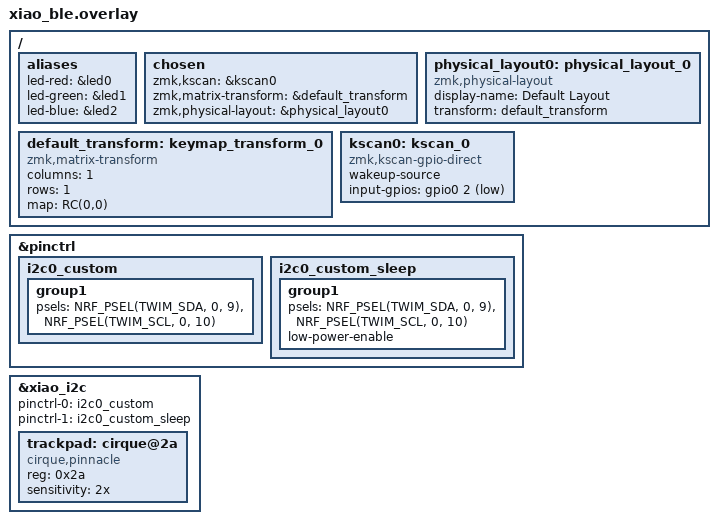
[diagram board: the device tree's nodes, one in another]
#include <dt-bindings/pinctrl/nrf-pinctrl.h>
#include <dt-bindings/zmk/matrix_transform.h>

/ {
    /* RGBLED Widget用のエイリアス設定（ハイフンを使用） */
    aliases {
        led-red = &led0;
        led-green = &led1;
        led-blue = &led2;
    };

    chosen {
        zmk,kscan = &kscan0;
        zmk,matrix-transform = &default_transform;
        zmk,physical-layout = &physical_layout0;
    };

    /* 1キーのみのダミーマトリックス配置 */
    default_transform: keymap_transform_0 {
        compatible = "zmk,matrix-transform";
        columns = <1>;
        rows = <1>;
        map = < RC(0,0) >;
    };

    /* 1キーのみの物理レイアウト定義 */
    physical_layout0: physical_layout_0 {
        compatible = "zmk,physical-layout";
        display-name = "Default Layout";
        transform = <&default_transform>;
    };

    /* D0ピン(P0.02)をスイッチ入力として定義 */
    kscan0: kscan_0 {
        compatible = "zmk,kscan-gpio-direct";
        wakeup-source;
        input-gpios = <&gpio0 2 (GPIO_ACTIVE_LOW | GPIO_PULL_UP)>;
    };
};

&pinctrl {
    /* I2Cピン設定: SDA=D9(P0.09), SCL=D10(P0.10) */
    i2c0_custom: i2c0_custom {
        group1 {
            psels = <NRF_PSEL(TWIM_SDA, 0, 9)>,
                    <NRF_PSEL(TWIM_SCL, 0, 10)>;
        };
    };
    i2c0_custom_sleep: i2c0_custom_sleep {
        group1 {
            psels = <NRF_PSEL(TWIM_SDA, 0, 9)>,
                    <NRF_PSEL(TWIM_SCL, 0, 10)>;
            low-power-enable;
        };
    };
};

&xiao_i2c {
    status = "okay";
    pinctrl-0 = <&i2c0_custom>;
    pinctrl-1 = <&i2c0_custom_sleep>;
    pinctrl-names = "default", "sleep";

    trackpad: cirque@2a {
        compatible = "cirque,pinnacle";
        reg = <0x2a>;
        status = "okay";
        /* エラーの原因となる GPIO 指定や sleep-mode をすべて削除 */
        sensitivity = "2x";
    };
};
